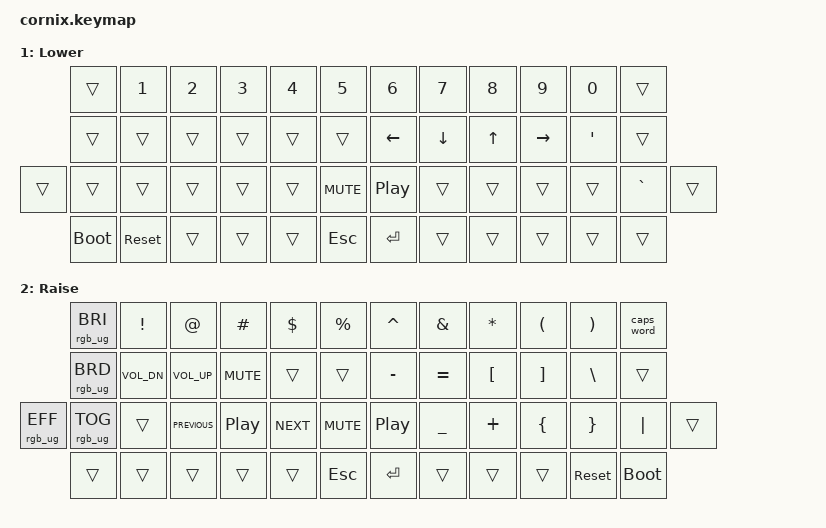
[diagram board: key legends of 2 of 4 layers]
/*
 * Copyright (c) 2020 The ZMK Contributors
 *
 * SPDX-License-Identifier: MIT
 */

#include <behaviors.dtsi>
#include <dt-bindings/zmk/keys.h>
#include <dt-bindings/zmk/bt.h>
#include <dt-bindings/zmk/rgb.h>
#include <dt-bindings/led/led.h>


#define HRML(k1,k2,k3,k4) &ht LSHFT k1  &ht LALT k2  &ht LCTRL k3  &ht LGUI k4
#define HRMR(k1,k2,k3,k4) &ht RGUI k1  &ht RCTRL k2  &ht RALT k3  &ht RSHFT k4

/ {
      behaviors {
        ht: hold_tap {
            compatible = "zmk,behavior-hold-tap";
            #binding-cells = <2>;
            flavor = "tap-preferred";
            tapping-term-ms = <220>;
            quick-tap-ms = <150>;
            require-prior-idle-ms = <100>;
            bindings = <&kp>, <&kp>;
        };
    };
      conditional_layers {
              compatible = "zmk,conditional-layers";
              tri_layer {
                if-layers = <1 2>;
                then-layer = <3>;
              };
        };
        keymap {
                compatible = "zmk,keymap";

                default_layer {
                        display-name = "Base";
                        bindings = <
   &trans  &kp Q &kp W &kp E &kp R  &kp T                         &kp Y &kp U  &kp I     &kp O   &kp P        &trans
   &trans HRML(A,  S,   D,    F)    &kp G                         &kp H HRMR(J,   K,    L,     SEMI)          &trans
   &trans   &kp Z &kp X &kp C &kp V &kp B &kp C_MUTE &kp C_PP     &kp N &kp M  &kp COMMA &kp DOT &kp FSLH     &trans
   &trans   &trans  &trans &trans &lt 1 TAB &kp SPACE          &kp RET   &lt 2 BSPC &trans &trans &trans &trans
                        >;
                        sensor-bindings = <&inc_dec_kp C_VOL_UP C_VOL_DN &inc_dec_kp PG_UP PG_DN>;
                };
                lower_layer {
                        display-name = "Lower";
                        bindings = <
   &trans  &kp N1       &kp N2       &kp N3       &kp N4       &kp N5         &kp N6   &kp N7   &kp N8 &kp N9    &kp N0  &trans
   &trans  &trans       &trans       &trans       &trans       &trans         &kp LEFT &kp DOWN &kp UP &kp RIGHT &kp SQT  &trans
   &trans  &trans       &trans       &trans       &trans       &trans &kp C_MUTE &kp C_PP        &trans   &trans   &trans &trans    &kp GRAVE &trans
   &bootloader  &sys_reset       &trans       &trans       &trans       &kp ESC        &kp RET  &trans   &trans &trans    &trans &trans
                        >;
                        sensor-bindings = <&inc_dec_kp C_VOL_UP C_VOL_DN &inc_dec_kp PG_UP PG_DN>;
                };

                raise_layer {
                        display-name = "Raise";
                        bindings = <
   &rgb_ug RGB_BRI  &kp EXCL       &kp AT       &kp HASH     &kp DLLR &kp PRCNT                             &kp CARET &kp AMPS  &kp ASTRK &kp LPAR &kp RPAR &caps_word
   &rgb_ug RGB_BRD  &kp C_VOL_DN   &kp C_VOL_UP &kp C_MUTE   &trans   &trans                                &kp MINUS &kp EQUAL &kp LBKT  &kp RBKT &kp BSLH &trans
   &rgb_ug RGB_EFF  &rgb_ug RGB_TOG   &trans &kp C_PREVIOUS   &kp C_PP   &kp C_NEXT &kp C_MUTE &kp C_PP                         &kp UNDER &kp PLUS  &kp LBRC  &kp RBRC &kp PIPE &trans
   &trans           &trans          &trans        &trans     &trans      &kp ESC                            &kp RET   &trans    &trans &trans &sys_reset    &bootloader  
                        >;
                        sensor-bindings = <&inc_dec_kp C_VOL_UP C_VOL_DN &inc_dec_kp PG_UP PG_DN>;
                };
                thrid_layer {
                        display-name = "System";
                        bindings = <
   &trans       &kp F1          &kp F2          &kp F3          &kp F4          &kp F5                                      &kp F6      &kp F7      &kp F8    &kp F9      &kp F10      &trans
   &bt BT_CLR   &bt BT_SEL 0    &bt BT_SEL 1    &bt BT_SEL 2    &bt BT_SEL 3    &bt BT_SEL 4                                &trans      &trans      &trans    &trans      &trans      &trans
   &trans       &trans          &trans          &trans          &trans        &kp C_MUTE &kp C_PP                              &trans      &trans      &trans    &trans      &trans      &trans
   &trans      &trans   &trans  &trans          &trans          &kp ESC                                                     &kp RET     &trans      &trans &trans &trans &trans
                        >;
                        sensor-bindings = <&inc_dec_kp C_VOL_UP C_VOL_DN &inc_dec_kp PG_UP PG_DN>;
                };
        };
};


